# AVR64DU32 register map
Vendor: Atmel; File version: 1.0
CPU: other r0p0, little endian, no MPU, no FPU, 4 interrupt priority bits
Registers are 8-bit, read-write, reset 0x0 unless marked. A register's access mark holds for its fields unless they carry their own. Offsets are from the block's base; [hi:lo] are bit positions; {n}, {i} and the like mark numbered series; 'fields as' and 'values as' point back to an identical list.

## USART0 — Universal Synchronous and Asynchronous Receiver and Transmitter
Base 0x00800800
Same registers: USART1 0x00800820
0x00 RXDATAL ro — Receive Data Low Byte
  [7:0] DATA — RX Data
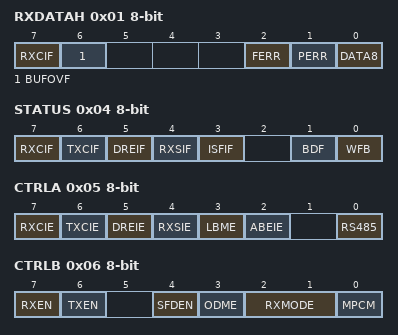
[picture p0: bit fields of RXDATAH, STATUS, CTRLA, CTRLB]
0x01 RXDATAH ro — Receive Data High Byte
  [7] RXCIF — Receive Complete Interrupt Flag
  [6] BUFOVF — Buffer Overflow
  [2] FERR — Frame Error
  [1] PERR — Parity Error
  [0] DATA8 — Receiver Data Register
0x02 TXDATAL — Transmit Data Low Byte
  [7:0] DATA — Transmit Data Register
0x03 TXDATAH — Transmit Data High Byte
  [0] DATA8 — Transmit Data Register (CHSIZE=9bit)
0x04 STATUS
  [7] RXCIF ro — Receive Complete Interrupt Flag
  [6] TXCIF — Transmit Interrupt Flag
  [5] DREIF ro — Data Register Empty Flag
  [4] RXSIF — Receive Start Interrupt
  [3] ISFIF — Inconsistent Sync Field Interrupt Flag
  [1] BDF — Break Detected Flag
  [0] WFB wo — Wait For Break
0x05 CTRLA — Control A
  [7] RXCIE — Receive Complete Interrupt Enable
  [6] TXCIE — Transmit Complete Interrupt Enable
  [5] DREIE — Data Register Empty Interrupt Enable
  [4] RXSIE — Receiver Start Frame Interrupt Enable
  [3] LBME — Loop-back Mode Enable
  [2] ABEIE — Auto-baud Error Interrupt Enable
  [0] RS485 — RS485 Mode internal transmitter
    0=DISABLE (RS485 Mode disabled); 1=ENABLE (RS485 Mode enabled)
0x06 CTRLB — Control B
  [7] RXEN — Reciever enable
  [6] TXEN — Transmitter Enable
  [4] SFDEN — Start Frame Detection Enable
  [3] ODME — Open Drain Mode Enable
  [2:1] RXMODE — Receiver Mode
    0=NORMAL (Normal mode); 1=CLK2X (CLK2x mode); 2=GENAUTO (Generic autobaud mode); 3=LINAUTO (LIN constrained autobaud mode)
  [0] MPCM — Multi-processor Communication Mode
0x07 CTRLC — Control C
  [7:6] CMODE — Communication Mode
    0=ASYNCHRONOUS (Asynchronous Mode); 1=SYNCHRONOUS (Synchronous Mode); 2=IRCOM (Infrared Communication); 3=MSPI (SPI Host Mode)
  [5:4] PMODE — Parity Mode
    0=DISABLED (No Parity); 2=EVEN (Even Parity); 3=ODD (Odd Parity)
  [3] SBMODE — Stop Bit Mode
    0=1BIT (1 stop bit); 1=2BIT (2 stop bits)
  [2] UDORD — SPI Host Mode, Data Order
  [1] UCPHA — SPI Host Mode, Clock Phase
  [2:0] CHSIZE — Character Size
    {v}={v+5}BIT (Character size: {v+5} bit) (v=0..3); 6=9BITL (Character size: 9 bit read low byte first); 7=9BITH (Character size: 9 bit read high byte first)
0x08 BAUD 16-bit (reset mask 0xFF) — Baud Rate
0x0A CTRLD — Control D
  [7:6] ABW — Auto Baud Window
    0=WDW0 (18% tolerance); 1=WDW1 (15% tolerance); 2=WDW2 (21% tolerance); 3=WDW3 (25% tolerance)
0x0B DBGCTRL — Debug Control
  [0] DBGRUN — Debug Run
0x0C EVCTRL — Event Control
  [0] IREI — IrDA Event Input Enable
0x0D TXPLCTRL — IRCOM Transmitter Pulse Length Control
  [7:0] TXPL — Transmit pulse length
0x0E RXPLCTRL — IRCOM Receiver Pulse Length Control
  [6:0] RXPL — Receiver Pulse Lenght

## USB0 — USB Device Controller
Base 0x00800C00
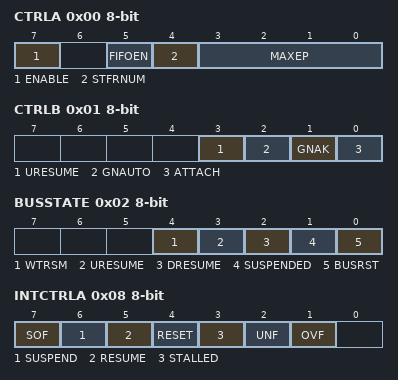
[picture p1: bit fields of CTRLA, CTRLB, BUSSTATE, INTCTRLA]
0x00 CTRLA — Control A
  [7] ENABLE — USB Enable
  [5] FIFOEN — Transaction Complete FIFO Enable
  [4] STFRNUM — Store Frame Number Enable
  [3:0] MAXEP — Maximum Endpoint Address
0x01 CTRLB — Control B
  [3] URESUME — Send Upstream Resume
  [2] GNAUTO — Set GNAK Automatically after SETUP
  [1] GNAK — Respond with NAK on all Endpoints
  [0] ATTACH
0x02 BUSSTATE ro
  [4] WTRSM — Wait Time Resume
  [3] URESUME — Upstream Resume
  [2] DRESUME — Downstram Resume
  [1] SUSPENDED — Bus Suspended
  [0] BUSRST — Bus Reset
0x03 ADDR — Address
  [6:0] ADDR — Device Address
0x04 FIFOWP — FIFO Write Pointer
  [4:0] FIFOWP
0x05 FIFORP — FIFO Read Pointer
  [4:0] FIFORP
0x06 EPPTR 16-bit (reset mask 0xFF) — Endpoint Configuration Table Pointer
  [15:0] EPPTR ro
0x08 INTCTRLA — Interrupt Control A
  [7] SOF — Start Of Frame Interrupt Enable
  [6] SUSPEND — Suspend Interrupt Enable
  [5] RESUME — Resume Interrupt Enable
  [4] RESET — Reset Interrupt Enable
  [3] STALLED — STALL Interrupt Enable
  [2] UNF — Underflow Interrupt Enable
  [1] OVF — Overflow Interrupt Enable
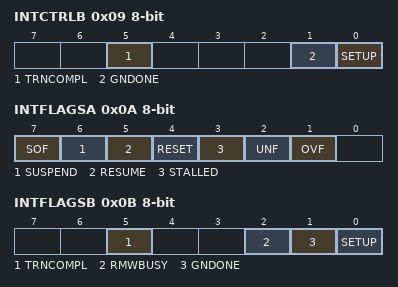
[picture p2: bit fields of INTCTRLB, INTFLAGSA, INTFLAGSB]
0x09 INTCTRLB — Interrupt Control B
  [5] TRNCOMPL — Transaction Complete Interrupt Enable
  [1] GNDONE — GNAK Operation Done Interrupt Enable
  [0] SETUP — SETUP Transaction Complete Interrupt Enable
0x0A INTFLAGSA — Interrupt Flags A
  [7] SOF — Start Of Frame Interrupt Flag
  [6] SUSPEND — Suspend Interrupt Flag
  [5] RESUME — Resume Interrupt Flag
  [4] RESET — Reset Interrupt Flag
  [3] STALLED — STALL Interrupt Flag
  [2] UNF — Underflow Interrupt Flag
  [1] OVF — Overflow Interrupt Flag
0x0B INTFLAGSB — Interrupt Flags B
  [5] TRNCOMPL — Transaction Complete Interrupt Flag
  [2] RMWBUSY — RMW Busy Flag
  [1] GNDONE — GNAK Operation Done Interrupt Flag
  [0] SETUP — SETUP Transaction Complete Interrupt Flag

## VPORTA — Virtual Ports
Base 0x00800000
Same registers: VPORTC 0x00800008, VPORTD 0x0080000C, VPORTF 0x00800014
0x00 DIR — Data Direction
0x01 OUT — Output Value
0x02 IN — Input Value
0x03 INTFLAGS — Interrupt Flags
  [7:0] INT — Pin Interrupt Flag

## VREF — Voltage reference
Base 0x008000B0
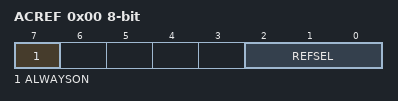
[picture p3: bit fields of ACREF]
0x00 ACREF — ADC0 Reference
  [7] ALWAYSON
  [2:0] REFSEL — Reference select
    0=1V024 (Internal 1.024V reference); 1=2V048 (Internal 2.048V reference); 2=4V096 (Internal 4.096V reference); 3=2V500 (Internal 2.500V reference); 5=VDD (VDD as reference); 6=VREFA (External reference on VREFA pin)

## WDT — Watch-Dog Timer
Base 0x00800100
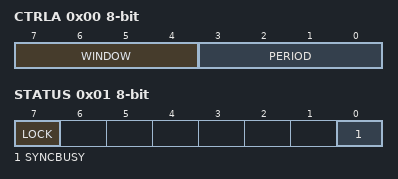
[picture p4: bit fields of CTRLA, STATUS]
0x00 CTRLA — Control A
  [7:4] WINDOW
    0=OFF; 1=8CLK (8 cycles (8ms)); 2=16CLK (16 cycles (16ms)); 3=32CLK (32 cycles (32ms)); 4=64CLK (64 cycles (64ms)); 5=128CLK (128 cycles (0.128s)); 6=256CLK (256 cycles (0.256s)); 7=512CLK (512 cycles (0.512s)); 8=1KCLK (1K cycles (1.0s)); 9=2KCLK (2K cycles (2.0s)); 10=4KCLK (4K cycles (4.1s)); 11=8KCLK (8K cycles (8.2s))
  [3:0] PERIOD
    values as WINDOW
0x01 STATUS
  [7] LOCK — Lock enable
  [0] SYNCBUSY ro — Syncronization busy
